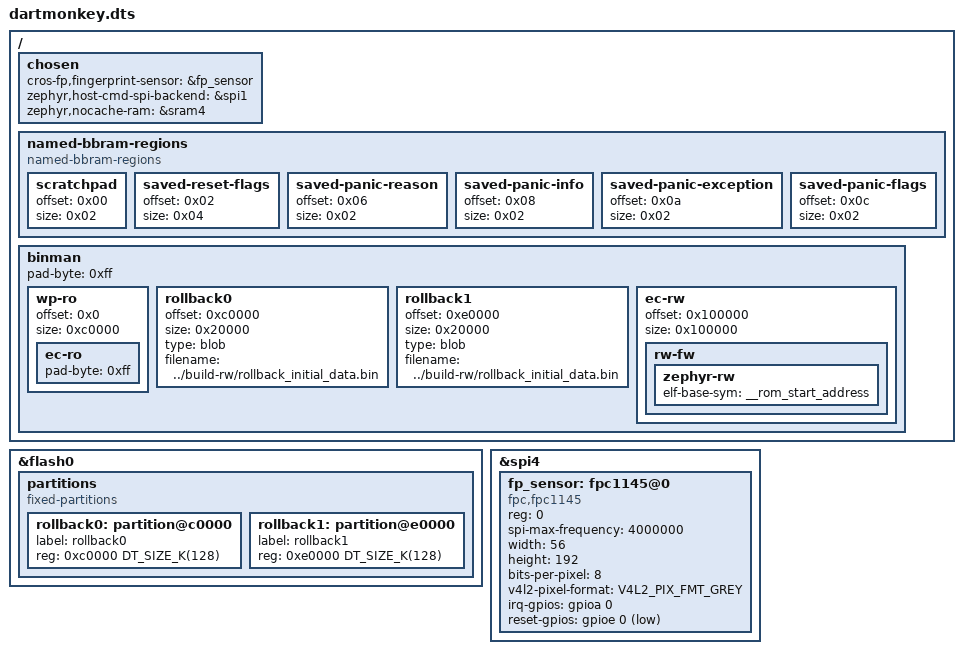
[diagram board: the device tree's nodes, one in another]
/* Copyright 2023 The ChromiumOS Authors.
 * Use of this source code is governed by a BSD-style license that can be
 * found in the LICENSE file.
 */

#include "soc.dtsi"
#include "gpio.dtsi"
#include "rwsig.dtsi"

#include <cros/integrated_fwid.dtsi>

/ {
	chosen {
		cros-fp,fingerprint-sensor = &fp_sensor;
		zephyr,host-cmd-spi-backend = &spi1;
		zephyr,nocache-ram = &sram4;
	};

	named-bbram-regions {
		compatible = "named-bbram-regions";

		scratchpad {
			offset = <0x00>;
			size = <0x02>;
		};
		// TODO check that with STM32_EXTENDED_RESET_FLAGS
		saved-reset-flags {
			offset = <0x02>;
			size = <0x04>;
		};
		saved-panic-reason {
			offset = <0x06>;
			size = <0x02>;
		};
		saved-panic-info {
			offset = <0x08>;
			size = <0x02>;
		};
		saved-panic-exception {
			offset = <0x0a>;
			size = <0x02>;
		};
		saved-panic-flags {
			offset = <0x0c>;
			size = <0x02>;
		};
	};

	binman {
		/* First 6 sectors (128KB each) used for RO */
		wp-ro {
			offset = <0x0>;
			size = <0xc0000>;
			ec-ro {
				pad-byte = <0xff>;
			};
		};

		/* Two sectors used for rollback (128KB each) */
		rollback0 {
			offset = <0xc0000>;
			size = <0x20000>;
			type = "blob";
			filename = "../build-rw/rollback_initial_data.bin";
		};

		rollback1 {
			offset = <0xe0000>;
			size = <0x20000>;
			type = "blob";
			filename = "../build-rw/rollback_initial_data.bin";
		};

		/* Remaining 8 sectors (128KB each) used for RW */
		ec-rw {
			offset = <0x100000>;
			size = <0x100000>;
			rw-fw {
				/*
				 * Clang doesn't emit STT_SECTION symbols (also
				 * called 'section symbols'), so 'rom_start'
				 * symbol is not available. Fortunately, Zephyr
				 * linker scripts provide '__rom_start_address'
				 * symbol which points to the beginning of
				 * 'rom_start' section.
				 */
				zephyr-rw {
					elf-base-sym = "__rom_start_address";
				};
			};
		};
		pad-byte = <0xff>;
	};
};

&flash0 {
	partitions {
		compatible = "fixed-partitions";
		#address-cells = <1>;
		#size-cells = <1>;

		/* Seventh sector is used as first rollback sector. */
		rollback0: partition@c0000 {
			label = "rollback0";
			reg = <0xc0000 DT_SIZE_K(128)>;
		};

		/* Eighth sector is used as second rollback sector. */
		rollback1: partition@e0000 {
			label = "rollback1";
			reg = <0xe0000 DT_SIZE_K(128)>;
		};
	};
};

&spi4 {
	fp_sensor: fpc1145@0 {
		compatible = "fpc,fpc1145";
		reg = <0>;
		spi-max-frequency = <4000000>;

		width = <56>;
		height = <192>;
		bits-per-pixel = <8>;
		v4l2-pixel-format = "V4L2_PIX_FMT_GREY";

		irq-gpios = <&gpioa 0 (GPIO_ACTIVE_HIGH | GPIO_PULL_DOWN)>;
		reset-gpios = <&gpioe 0 GPIO_ACTIVE_LOW>;
	};
};
